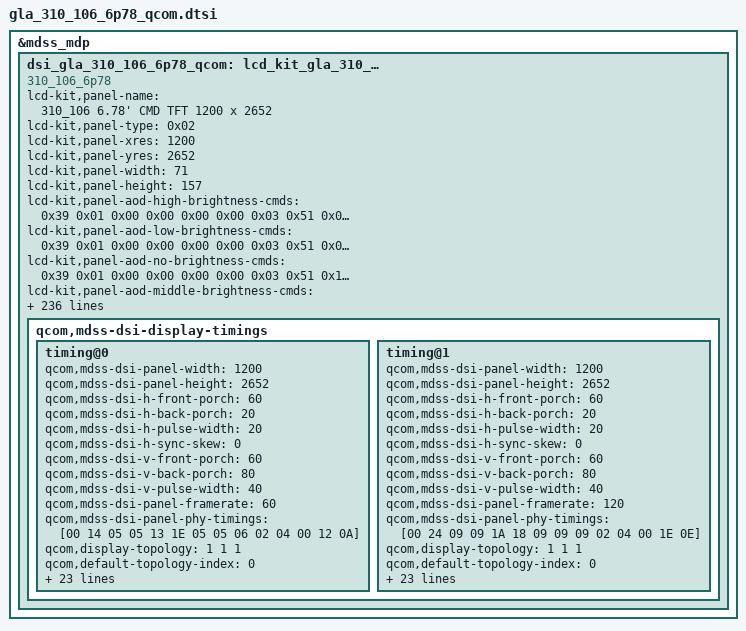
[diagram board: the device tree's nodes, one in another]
/* Copyright (c) 2013, The Linux Foundation. All rights reserved.
 *
 * This program is free software; you can redistribute it and/or modify
 * it under the terms of the GNU General Public License version 2 and
 * only version 2 as published by the Free Software Foundation.
 *
 * This program is distributed in the hope that it will be useful,
 * but WITHOUT ANY WARRANTY; without even the implied warranty of
 * MERCHANTABILITY or FITNESS FOR A PARTICULAR PURPOSE.  See the
 * GNU General Public License for more details.
 */

/*-------------------------------------------------------------------------
 * This file is autogenerated file using gcdb parser. Please do not edit it.
 * Update input XML file to add a new entry or update variable in this file
 * VERSION = 1.1
 *-----------------------------------------------------------------------*/
&mdss_mdp {
	dsi_gla_310_106_6p78_qcom: lcd_kit_gla_310_106_6p78_qcom {
		compatible = "310_106_6p78";
		lcd-kit,panel-name = "310_106 6.78' CMD TFT 1200 x 2652";
		lcd-kit,panel-type = <0x02>;
		lcd-kit,panel-xres = <1200>;
		lcd-kit,panel-yres = <2652>;
		lcd-kit,panel-width = <71>;
		lcd-kit,panel-height = <157>;
		lcd-kit,panel-aod-high-brightness-cmds = <0x39 0x01 0x00 0x00 0x00 0x00 0x03 0x51 0x0F 0xFE>;
		lcd-kit,panel-aod-low-brightness-cmds = <0x39 0x01 0x00 0x00 0x00 0x00 0x03 0x51 0x01 0x24>;
		lcd-kit,panel-aod-no-brightness-cmds = <0x39 0x01 0x00 0x00 0x00 0x00 0x03 0x51 0x10 0x00>;
		lcd-kit,panel-aod-middle-brightness-cmds = <0x39 0x01 0x00 0x00 0x00 0x00 0x03 0x51 0x06 0xDB>;
		lcd-kit,pcd-check-reg-cmds = <0x20>;
		lcd-kit,check-reg-on-cmds = <0x06 0x01 0x00 0x00 0x0a 0x00 0x01 0x0a>;
		lcd-kit,check-reg-on-value = <0x9c>;
		lcd-kit,check-aod-reg-on-cmds = <0x06 0x01 0x00 0x00 0x0a 0x00 0x01 0x0a>;
		lcd-kit,check-aod-reg-on-value = <0xdc>;
		lcd-kit,check-reg-off-cmds = <0x06 0x01 0x00 0x00 0x0a 0x00 0x01 0x0a>;
		lcd-kit,check-reg-off-value = <0x08>;
		lcd-kit,check-reg-on-cmds-state = "dsi_lp_mode";
		lcd-kit,check-aod-reg-on-cmds-state = "dsi_lp_mode";
		lcd-kit,check-reg-off-cmds-state = "dsi_lp_mode";
		lcd-kit,pcd-check-reg-value = <0x20>;
		lcd-kit,pcd-errflag-check-support = <0>;
		lcd-kit,checksum-enable-cmds = <0x39 0x01 0x00 0x00 0x14 0x00 0x05 0xFF 0xAA 0x55 0xA5 0x80
		0x15 0x01 0x00 0x00 0x0a 0x00 0x02 0xF2 0x03>;
		lcd-kit,checksum-enable-cmds-state = "dsi_lp_mode";
		lcd-kit,checksum-disable-cmds = <0x39 0x01 0x00 0x00 0x14 0x00 0x05 0xFF 0xAA 0x55 0xA5 0x80
		0x15 0x01 0x00 0x00 0x0a 0x00 0x02 0xF2 0x00>;
		lcd-kit,checksum-disable-cmds-state = "dsi_lp_mode";
		lcd-kit,checksum-cmds = <0x39 0x01 0x00 0x00 0x14 0x00 0x05 0xFF 0xAA 0x55 0xA5 0x80
		0x15 0x01 0x00 0x00 0x0a 0x00 0x02 0x6F 0x01
		0x14 0x01 0x00 0x00 0x0a 0x00 0x08 0xF2 0x00 0x00 0x00 0x00 0x00 0x00 0x00>;
		lcd-kit,checksum-cmds-state = "dsi_lp_mode";
		lcd-kit,checksum-value = <0x06 0xf2 0x7d 0x83 0x91 0xe7 0x4c 0x2a
		0xba 0xeb 0x79 0x7c 0xe4 0xb4 0xcb 0x62
		0x97 0x89 0xd0 0x7a 0xc4 0xee 0xf7 0x69>;
		lcd-kit,hor-line-cmds = <0x39 0x01 0x00 0x00 0x0a 0x00 0x06 0xF0 0x55 0xAA 0x52 0x08 0x01
		0x15 0x01 0x00 0x00 0x0a 0x00 0x02 0xB3 0x23
		0x15 0x01 0x00 0x00 0x0a 0x00 0x02 0xB4 0x23
		0x15 0x01 0x00 0x00 0x0a 0x00 0x02 0xB0 0x0B
		0x15 0x01 0x00 0x00 0x0a 0x00 0x02 0xB1 0x08
		0x39 0x01 0x00 0x00 0x0a 0x00 0x09 0xB7 0x46 0x46 0x46 0x46 0x46 0x46 0x46 0x46
		0x39 0x01 0x00 0x00 0x0a 0x00 0x08 0xB8 0x5F 0x5F 0x5F 0x5F 0x5F 0x5F 0x5F
		0x15 0x01 0x00 0x00 0x0a 0x00 0x02 0x2F 0x03
		0x39 0x01 0x00 0x00 0x0a 0x00 0x06 0xF0 0x55 0xAA 0x52 0x08 0x00
		0x39 0x01 0x00 0x00 0x0a 0x00 0x03 0xB2 0x11 0x00
		0x39 0x01 0x00 0x00 0x0a 0x00 0x03 0x51 0x00 0x00
		0x39 0x01 0x00 0x00 0x0a 0x00 0x06 0xF0 0x55 0xAA 0x52 0x08 0x06
		0x15 0x01 0x00 0x00 0x0a 0x00 0x02 0x6F 0x02
		0x39 0x01 0x00 0x00 0x0a 0x00 0x03 0xB1 0x31 0x31
		0x15 0x01 0x00 0x00 0x0a 0x00 0x02 0x6F 0x02
		0x39 0x01 0x00 0x00 0x0a 0x00 0x03 0xB7 0x31 0x31>;
		lcd-kit,hor-line-cmds-state = "dsi_lp_mode";
		lcd-kit,pcd-read-cmds = <0x15 0x01 0x00 0x00 0x00 0x00 0x02 0xB0 0x00
		0x15 0x01 0x00 0x00 0x00 0x00 0x02 0x00 0x00
		0x39 0x01 0x00 0x00 0x00 0x00 0x0D 0xDD 0x88 0x00 0x41 0x09 0x00 0x45 0x81 0x00 0x00 0x00 0x00 0x00
		0x39 0x01 0x00 0x00 0x00 0x00 0x0B 0xF7 0x00 0x00 0x00 0x00 0x00 0x00 0x00 0x00 0x20 0x00
		0x15 0x01 0x00 0x00 0x00 0x00 0x02 0xB0 0x00
		0x15 0x01 0x00 0x00 0x00 0x00 0x02 0x00 0x00
		0x15 0x01 0x00 0x00 0x00 0x00 0x02 0xF1 0x01
		0x06 0x01 0x00 0x00 0x00 0x00 0x01 0xB4
		0x15 0x01 0x00 0x00 0x00 0x00 0x02 0xB0 0x00
		0x15 0x01 0x00 0x00 0x00 0x00 0x02 0x00 0x00
		0x39 0x01 0x00 0x00 0x00 0x00 0x0D 0xDD 0x00 0x00 0x41 0x28 0x00 0x41 0x80 0x00 0x00 0x00 0x00 0x00
		0x39 0x01 0x00 0x00 0x00 0x00 0x0B 0xF7 0x00 0x00 0x00 0x00 0x00 0x00 0x00 0x00 0x00 0x00>;
		lcd-kit,pcd-read-cmds-state  = "dsi_lp_mode";
		lcd-kit,vtc-line-cmds = <0x39 0x01 0x00 0x00 0x0a 0x00 0x06 0xF0 0x55 0xAA 0x52 0x08 0x00
		0x15 0x01 0x00 0x00 0x0a 0x00 0x02 0x6F 0x06
		0x15 0x01 0x00 0x00 0x0a 0x00 0x02 0xB5 0x4E
		0x39 0x01 0x00 0x00 0x0a 0x00 0x06 0xF0 0x55 0xAA 0x52 0x08 0x01
		0x15 0x01 0x00 0x00 0x0a 0x00 0x02 0xCF 0x00
		0x39 0x01 0x00 0x00 0x0a 0x00 0x03 0xB5 0x00 0xF0
		0x39 0x01 0x00 0x00 0x0a 0x00 0x03 0xB6 0x01 0x60
		0x39 0x01 0x00 0x00 0x0a 0x00 0x06 0xF0 0x55 0xAA 0x52 0x08 0x00
		0x15 0x01 0x00 0x00 0x0a 0x00 0x02 0xC5 0x01
		0x39 0x01 0x00 0x00 0x0a 0x00 0x06 0xF0 0x55 0xAA 0x52 0x08 0x05
		0x15 0x01 0x00 0x00 0x0a 0x00 0x02 0xEC 0x01
		0x39 0x01 0x00 0x00 0x0a 0x00 0x03 0x51 0x0F 0xFF
		0x15 0x01 0x00 0x00 0x0a 0x00 0x02 0x53 0x20
		0x39 0x01 0x00 0x00 0x0a 0x00 0x06 0xF0 0x55 0xAA 0x52 0x08 0x01
		0x15 0x01 0x00 0x00 0x0a 0x00 0x02 0xB3 0x23
		0x15 0x01 0x00 0x00 0x0a 0x00 0x02 0xB4 0x23
		0x15 0x01 0x00 0x00 0x0a 0x00 0x02 0xB0 0x0B
		0x15 0x01 0x00 0x00 0x0a 0x00 0x02 0xB1 0x08
		0x39 0x01 0x00 0x00 0x0a 0x00 0x09 0xB7 0x46 0x46 0x46 0x46 0x46 0x46 0x46 0x46
		0x39 0x01 0x00 0x00 0x0a 0x00 0x08 0xB8 0x5F 0x5F 0x5F 0x5F 0x5F 0x5F 0x5F
		0x39 0x01 0x00 0x00 0x0a 0x00 0x06 0xF0 0x55 0xAA 0x52 0x08 0x07
		0x39 0x01 0x00 0x00 0x0a 0x00 0x07 0xB1 0x10 0x60 0x40 0x00 0x20 0x50
		0x05 0x01 0x00 0x00 0x46 0x01 0x01 0x11
		0x05 0x01 0x00 0x00 0x0a 0x01 0x01 0x28>;
		lcd-kit,vtc-line-cmds-state  = "dsi_lp_mode";
		lcd-kit,ddic-lv-det-enter1-cmds = <0x39 0x01 0x00 0x00 0x0a 0x00 0x06 0xF0 0x55 0xAA 0x52 0x08 0x01
		0x39 0x01 0x00 0x00 0x14 0x00 0x05 0xC7 0x68 0x34 0x30 0x0F>;
		lcd-kit,ddic-lv-det-enter1-cmds-state  = "dsi_lp_mode";
		lcd-kit,ddic-lv-det-enter2-cmds = <0x39 0x01 0x00 0x00 0x0a 0x00 0x06 0xF0 0x55 0xAA 0x52 0x08 0x01
		0x39 0x01 0x00 0x00 0x14 0x00 0x05 0xC7 0x68 0x34 0x30 0x0F>;
		lcd-kit,ddic-lv-det-enter2-cmds-state  = "dsi_lp_mode";
		lcd-kit,ddic-lv-det-enter3-cmds = <0x39 0x01 0x00 0x00 0x0a 0x00 0x06 0xF0 0x55 0xAA 0x52 0x08 0x01
		0x39 0x01 0x00 0x00 0x14 0x00 0x05 0xC7 0x68 0x34 0x30 0x0F>;
		lcd-kit,ddic-lv-det-enter3-cmds-state  = "dsi_lp_mode";
		lcd-kit,ddic-lv-det-enter4-cmds = <0x39 0x01 0x00 0x00 0x0a 0x00 0x06 0xF0 0x55 0xAA 0x52 0x08 0x01
		0x39 0x01 0x00 0x00 0x14 0x00 0x05 0xC7 0x68 0x34 0x30 0x0F>;
		lcd-kit,ddic-lv-det-enter4-cmds-state  = "dsi_lp_mode";
		lcd-kit,ddic-lv-det-rd1-cmds = <0x06 0x01 0x00 0x00 0x0a 0x00 0x01 0x0a>;
		lcd-kit,ddic-lv-det-rd1-cmds-state  = "dsi_lp_mode";
		lcd-kit,ddic-lv-det-rd2-cmds = <0x06 0x01 0x00 0x00 0x0a 0x00 0x01 0x0a>;
		lcd-kit,ddic-lv-det-rd2-cmds-state  = "dsi_lp_mode";
		lcd-kit,ddic-lv-det-rd3-cmds = <0x06 0x01 0x00 0x00 0x0a 0x00 0x01 0x0a>;
		lcd-kit,ddic-lv-det-rd3-cmds-state  = "dsi_lp_mode";
		lcd-kit,ddic-lv-det-rd4-cmds = <0x06 0x01 0x00 0x00 0x0a 0x00 0x01 0x0a>;
		lcd-kit,ddic-lv-det-rd4-cmds-state  = "dsi_lp_mode";
		lcd-kit,ddic-lv-det-value1 = <0x9c>;
		lcd-kit,ddic-lv-det-value2 = <0x9c>;
		lcd-kit,ddic-lv-det-value3 = <0x9c>;
		lcd-kit,ddic-lv-det-value4 = <0x9c>;
		lcd-kit,bl-after-frame = <0>;
		lcd-kit,cmd-async-support = <0>;
		lcd-kit,ap-aod-support = <1>;
		lcd-kit,mask-delay-time-before-fp = <16667>;
		lcd-kit,mask-delay-time-after-fp = <16667>;
		lcd-kit,left-time-to-te-us = <28667>;
		lcd-kit,right-time-to-te-us = <29667>;
		lcd-kit,te-interval-time-us = <16667>;
		lcd-kit,oneside-mode-support = <0>;
		lcd-kit,color-aod-detect-support = <0>;
		lcd-kit,elvdd-detect-support = <0>;
		lcd-kit,elvdd-detect-type = <2>;
		lcd-kit,elvdd-detect-value = <1>;
		lcd-kit,elvdd-delay = <50>;
		lcd-kit,elvdd-detect-gpio = <104>;
		lcd-kit,check-reg-on-support = <0>;
		lcd-kit,check-reg-on-support-dsm-report = <0>;
		lcd-kit,check-aod-reg-on-support = <0>;
		lcd-kit,check-aod-reg-on-support-dsm-report = <0>;
		lcd-kit,check-reg-off-support = <0>;
		lcd-kit,check-reg-off-support-dsm-report = <0>;
		lcd-kit,checksum-support = <0>;
		lcd-kit,pcd-cmds-support = <1>;
		lcd-kit,pcd-check-reg-value-compare-mode = <0>;
		lcd-kit,vtc-line-support = <0>;
		lcd-kit,ddic-lv-det-support = <0>;
		lcd-kit,hor-line-support = <0>;
		lcd-kit,hor-line-duration = <600>;
		lcd-kit,vtc-line-no-reset = <1>;
		qcom,mdss-dsi-panel-type = "dsi_cmd_mode";
		qcom,mdss-pan-physical-width-dimension = <71>;
		qcom,mdss-pan-physical-height-dimension = <157>;
		qcom,dsi-ctrl-num = <0>;
		qcom,dsi-phy-num = <0>;
		qcom,panel-supply-entries = <&dsi_panel_pwr_supply>;
		qcom,mdss-dsi-virtual-channel-id = <0>;
		qcom,mdss-dsi-h-sync-pulse = <0>;
		qcom,mdss-dsi-bllp-eof-power-mode;
		qcom,mdss-dsi-bllp-power-mode;
		qcom,mdss-dsi-dma-schedule-line = <1>;
		qcom,mdss-dsi-bpp = <24>;
		qcom,mdss-dsi-color-order = "rgb_swap_rgb";
		qcom,mdss-dsi-underflow-color = <0xff>;
		qcom,mdss-dsi-border-color = <0>;
		qcom,mdss-dsi-traffic-mode = "burst_mode";
		qcom,mdss-dsi-lane-map = "lane_map_0123";
		qcom,mdss-dsi-lane-0-state;
		qcom,mdss-dsi-lane-1-state;
		qcom,mdss-dsi-lane-2-state;
		qcom,mdss-dsi-lane-3-state;
		qcom,mdss-dsi-mdp-trigger = "none";
		qcom,mdss-dsi-dma-trigger = "trigger_sw";
		qcom,mdss-dsi-te-pin-select = <1>;
		qcom,mdss-dsi-wr-mem-start = <0x2c>;
		qcom,mdss-dsi-wr-mem-continue = <0x3c>;
		qcom,mdss-dsi-te-dcs-command = <1>;
		qcom,mdss-dsi-te-check-enable;
		qcom,mdss-dsi-te-using-te-pin;
		qcom,dsi-panel-gpio-address = <0x0F100000 0x1000>;
		qcom,dsi-panel-gpio-pins = <12 44 80>;
		qcom,dsi-panel-gpio-names = "reg-gpio", "reset-gpio", "platform-te-gpio";
		qcom,mdss-dsi-t-clk-post = <0>;
		qcom,mdss-dsi-t-clk-pre = <0>;
		qcom,dsi-select-clocks = "mux_byte_clk0", "mux_pixel_clk0";
		qcom,mdss-dsi-stream = <0>;
		lcd-kit,check-thread-support = <0>;
		lcd-kit,check-time-period = <5000>;
		lcd-kit,check-fold-support = <0>;
		lcd-kit,fold-low-power-support = <0>;
		lcd-kit,fold-height = <0>;
		lcd-kit,unfold-height = <0>;
		lcd-kit,power-support = <0>;
		lcd-kit,three-stage-poweron = <1>;
		lcd-kit,fold-lp-time = <0>;
		lcd-kit,fold-nolp-time = <0>;
		qcom,sublinks-count = <2>;
		qcom,lanes-per-sublink = <2>;
		qcom,mdss-dsi-panel-hdr-color-primaries = <14500 15500 32000 17000 15500 30000 8000 3000>;
		qcom,mdss-dsi-panel-peak-brightness = <4200000>;
		qcom,mdss-dsi-panel-blackness-level = <3230>;
		qcom,dynamic-mode-switch-enabled;
		qcom,dynamic-mode-switch-type = "dynamic-resolution-switch-immediate";
		qcom,mdss-dsi-bl-pmic-control-type = "bl_ctrl_dcs";
		qcom,mdss-dsi-bl-min-level = <1>;
		qcom,mdss-dsi-bl-max-level = <10000>;
		qcom,esd-check-enabled;
		qcom,mdss-dsi-panel-status-command = [06 01 00 00 00 00 01 0A
			06 01 00 00 00 00 01 03
			15 01 00 00 00 00 02 B0 00
			15 01 00 00 00 00 02 00 00
			06 01 00 00 00 00 02 F8 00
			06 01 00 00 00 00 01 C3
			15 01 00 00 00 00 02 B0 03
			15 01 00 00 00 00 02 00 00];
		qcom,mdss-dsi-panel-status-command-state = "dsi_lp_mode";
		qcom,mdss-dsi-panel-status-check-mode = "reg_read";
		qcom,mdss-dsi-panel-status-read-length = <1 1 0 0 2 1 0 0>;
		qcom,mdss-dsi-panel-status-value = <0x1C>,<0x00>,<0x11 0x00>,<0x00>;
		lcd-kit,power-on-stage = <2 1 3
				1 1 1
				9 1 15>;
		lcd-kit,lp-on-stage = <5 1 5
				5 0 2
				5 1 30
				7 1 0
				6 1 0
				8 1 0>;
		lcd-kit,lp-off-stage = <0 0 0>;
		lcd-kit,power-off-stage = <7 0 0
				6 0 0
				8 0 0
				5 0 2
				9 0 1
				1 0 2
				2 0 1>;
		lcd-kit,only-power-off-stage = <0 0 0>;
		lcd-kit,pt-support = <1>;
		lcd-kit,panel-on-always-reset = <0>;
		lcd-kit,lcd-vci = <1 13 3000000 3000000 3000000 10000 80>;
		lcd-kit,lcd-iovcc = <1 12 1800000 1800000 1800000 60700 80>;
		lcd-kit,lcd-vdd = <1 16 1240000 1240000 1240000 30000 80>;
		lcd-kit,lcd-reset = <2 44 0>;
		lcd-kit,lcd-vci-name = "vdd";
		lcd-kit,lcd-iovcc-name = "vddio";
		lcd-kit,lcd-vdd-name = "ddic";
		lcd-kit,project-id-support = <0>;
		lcd-kit,default-project-id = "B2359S2920";
		lcd-kit,sn-code-support = <1>;
		lcd-kit,oem-info-support = <1>;
		lcd-kit,oem-barcode-2d-support = <1>;
		lcd-kit,oem-barcode-2d-num-offset = <0>;
		lcd-kit,barcode-2d-cmds = <0x15 0x01 0x00 0x00 0x00 0x00 0x02 0xB0 0x40
		0x15 0x01 0x00 0x00 0x00 0x00 0x02 0x00 0x00
		0x14 0x01 0x00 0x00 0x00 0x00 0x15 0xBE 0x00 0x00 0x00 0x00 0x00 0x00 0x00 0x00 0x00 0x00 0x00 0x00 0x00 0x00 0x00 0x00 0x00 0x00 0x00 0x00
		0x15 0x01 0x00 0x00 0x00 0x00 0x02 0xB0 0x03
		0x15 0x01 0x00 0x00 0x00 0x00 0x02 0x00 0x00>;
		lcd-kit,barcode-2d-cmds-state = "dsi_lp_mode";
		lcd-kit,panel-getblmaxnit-type = <0>;
		lcd-kit,panel-blmaxnit-min-value = <400>;
		lcd-kit,inversion-support = <0>;
		lcd-kit,panel-gpio-offset = <336>;
		lcd-kit,finger-unlock-state-support = <0>;
		lcd-kit,finger-handle-esd-support = <1>;
		lcd-kit,esd-reg-te-check = <0>;
		lcd-kit,dump-support = <0>;
		lcd-kit,underflow-support = <1>;
		lcd-kit,panel-bl-max-nit = <450>;
		lcd-kit,panel-bl-min = <9>;
		lcd-kit,panel-bl-max = <10000>;
		lcd-kit,panel-bl-def = <2047>;
		lcd-kit,check-reg-support = <0>;
		lcd-kit,thp-proximity-support = <0>;
		lcd-kit,proximity-reset-delay-min = <65>;
		lcd-kit,backlight-cmds = <0x39 0x01 0x00 0x00 0x00 0x00 0x03 0x51 0x00 0x00>;
		lcd-kit,backlight-cmds-state = "dsi_lp_mode";
		lcd-kit,backlight-order = <0>;
		lcd-kit,backlight-need-sync = <0>;
		lcd-kit,backlight-write-offset = <0x10>;
		lcd-kit,fps-support = <1>;
		lcd-kit,default-fps = <60>;
		lcd-kit,panel-support-fps-list = <60 120>;
		lcd-kit,fps-60-cmd = "vndservice call display.qservice 25 i32 0 i32 0";
		lcd-kit,fps-90-cmd = "vndservice call display.qservice 25 i32 2 i32 0";
		lcd-kit,fps-120-cmd = "vndservice call display.qservice 25 i32 1 i32 0";
		qcom,mdss-dsi-display-timings {
			timing@0 {
				qcom,mdss-dsi-panel-width = <1200>;
				qcom,mdss-dsi-panel-height = <2652>;
				qcom,mdss-dsi-h-front-porch = <60>;
				qcom,mdss-dsi-h-back-porch = <20>;
				qcom,mdss-dsi-h-pulse-width = <20>;
				qcom,mdss-dsi-h-sync-skew = <0>;
				qcom,mdss-dsi-v-front-porch = <60>;
				qcom,mdss-dsi-v-back-porch = <80>;
				qcom,mdss-dsi-v-pulse-width = <40>;
				qcom,mdss-dsi-panel-framerate = <60>;
				qcom,mdss-dsi-panel-phy-timings= [00 14 05 05 13 1E 05
			05 06 02 04 00 12 0A];
				qcom,display-topology  = <1 1 1>;
				qcom,default-topology-index  = <0>;
				qcom,mdss-dsi-on-command = [15 01 00 00 00 00 02 B0 00
		15 01 00 00 00 00 02 00 00
		15 01 00 00 00 00 02 F1 03
		15 01 00 00 00 00 02 F8 AB
		15 01 00 00 00 00 02 F1 24
		39 01 00 00 00 00 08 F8 07 10 20 00 06 0F 0F
		15 01 00 00 00 00 02 F1 3A
		39 01 00 00 00 00 1F F8 02 02 22 00 2A 40 2A BE 3A FC 3A FA 3A F8 3B 38 3B 78 3B B6 4B B6 4B F4 4B F4 6C 34 84 74
		15 01 00 00 00 00 02 B0 00
		15 01 00 00 00 00 02 00 00
		39 01 00 00 00 00 03 F6 88 88
		15 01 00 00 00 00 02 B0 20
		15 01 00 00 00 00 02 00 00
		15 01 00 00 00 00 02 C2 39
		15 01 00 00 00 00 02 B0 00
		15 01 00 00 00 00 02 00 00
		39 01 00 00 00 00 04 E3 00 00 01
		39 01 00 00 00 00 04 B2 30 6C A6
		15 01 00 00 00 00 02 B0 04
		15 01 00 00 00 00 02 00 00
		15 01 00 00 00 00 02 DE 40
		15 01 00 00 00 00 02 80 01
		39 01 00 00 00 00 05 2A 00 00 04 AF
		39 01 00 00 00 00 05 2B 00 00 0A 5B
		15 01 00 00 00 00 02 35 00
		15 01 00 00 00 00 02 53 20
		15 01 00 00 00 00 02 B0 03
		15 01 00 00 00 00 02 00 00
		05 01 00 00 A0 00 01 11
		05 01 00 00 14 00 01 29];
				qcom,mdss-dsi-on-command-state = "dsi_lp_mode";
				qcom,mdss-dsi-off-command = [05 01 00 00 00 00 01 28
		05 01 00 00 5D 00 01 10];
				qcom,mdss-dsi-off-command-state = "dsi_lp_mode";
				qcom,compression-mode = "dsc";
				qcom,mdss-dsc-slice-height = <12>;
				qcom,mdss-dsc-slice-width = <600>;
				qcom,mdss-dsc-slice-per-pkt = <2>;
				qcom,mdss-dsc-bit-per-component = <10>;
				qcom,mdss-dsc-bit-per-pixel = <8>;
				qcom,mdss-dsc-block-prediction-enable;
				qcom,mdss-dsi-timing-switch-command = [15 01 00 00 11 00 02 80 01];
				qcom,mdss-dsi-timing-switch-command-state = "dsi_lp_mode";
				qcom,mdss-dsi-lp1-command = [39 01 00 00 00 00 03 51 10 00
		15 01 00 00 00 00 02 B0 00
		15 01 00 00 00 00 02 00 00
		15 01 00 00 00 00 02 F1 09
		39 01 00 00 00 00 03 C5 00 AA
		15 01 00 00 00 00 02 B0 03
		15 01 00 00 00 00 02 00 00
		05 01 00 00 00 00 01 39];
				qcom,mdss-dsi-lp1-command-state = "dsi_lp_mode";
				qcom,mdss-dsi-nolp-command = [39 01 00 00 00 00 03 51 10 00
		15 01 00 00 00 00 02 B0 00
		15 01 00 00 00 00 02 00 00
		15 01 00 00 00 00 02 F1 09
		39 01 00 00 00 00 03 C5 05 0A
		15 01 00 00 00 00 02 B0 03
		15 01 00 00 00 00 02 00 00
		05 01 00 00 00 00 01 38];
				qcom,mdss-dsi-nolp-command-state = "dsi_lp_mode";
			};
			timing@1 {
				qcom,mdss-dsi-panel-width = <1200>;
				qcom,mdss-dsi-panel-height = <2652>;
				qcom,mdss-dsi-h-front-porch = <60>;
				qcom,mdss-dsi-h-back-porch = <20>;
				qcom,mdss-dsi-h-pulse-width = <20>;
				qcom,mdss-dsi-h-sync-skew = <0>;
				qcom,mdss-dsi-v-front-porch = <60>;
				qcom,mdss-dsi-v-back-porch = <80>;
				qcom,mdss-dsi-v-pulse-width = <40>;
				qcom,mdss-dsi-panel-framerate = <120>;
				qcom,mdss-dsi-panel-phy-timings= [00 24 09 09 1A 18 09
			09 09 02 04 00 1E 0E];
				qcom,display-topology  = <1 1 1>;
				qcom,default-topology-index  = <0>;
				qcom,mdss-dsi-on-command = [15 01 00 00 00 00 02 B0 00
		15 01 00 00 00 00 02 00 00
		15 01 00 00 00 00 02 F1 03
		15 01 00 00 00 00 02 F8 AB
		15 01 00 00 00 00 02 F1 24
		39 01 00 00 00 00 08 F8 07 10 20 00 06 0F 0F
		15 01 00 00 00 00 02 F1 3A
		39 01 00 00 00 00 1F F8 02 02 22 00 2A 40 2A BE 3A FC 3A FA 3A F8 3B 38 3B 78 3B B6 4B B6 4B F4 4B F4 6C 34 84 74
		15 01 00 00 00 00 02 B0 00
		15 01 00 00 00 00 02 00 00
		39 01 00 00 00 00 03 F6 88 88
		15 01 00 00 00 00 02 B0 20
		15 01 00 00 00 00 02 00 00
		15 01 00 00 00 00 02 C2 39
		15 01 00 00 00 00 02 B0 00
		15 01 00 00 00 00 02 00 00
		39 01 00 00 00 00 04 E3 00 00 01
		39 01 00 00 00 00 04 B2 30 6C A6
		15 01 00 00 00 00 02 B0 04
		15 01 00 00 00 00 02 00 00
		15 01 00 00 00 00 02 DE 40
		15 01 00 00 00 00 02 80 10
		39 01 00 00 00 00 05 2A 00 00 04 AF
		39 01 00 00 00 00 05 2B 00 00 0A 5B
		15 01 00 00 00 00 02 35 00
		15 01 00 00 00 00 02 53 20
		15 01 00 00 00 00 02 B0 03
		15 01 00 00 00 00 02 00 00
		05 01 00 00 A0 00 01 11
		05 01 00 00 14 00 01 29];
				qcom,mdss-dsi-on-command-state = "dsi_lp_mode";
				qcom,mdss-dsi-off-command = [05 01 00 00 00 00 01 28
		05 01 00 00 5D 00 01 10];
				qcom,mdss-dsi-off-command-state = "dsi_lp_mode";
				qcom,compression-mode = "dsc";
				qcom,mdss-dsc-slice-height = <12>;
				qcom,mdss-dsc-slice-width = <600>;
				qcom,mdss-dsc-slice-per-pkt = <2>;
				qcom,mdss-dsc-bit-per-component = <10>;
				qcom,mdss-dsc-bit-per-pixel = <8>;
				qcom,mdss-dsc-block-prediction-enable;
				qcom,mdss-dsi-timing-switch-command = [15 01 00 00 11 00 02 80 10];
				qcom,mdss-dsi-timing-switch-command-state = "dsi_lp_mode";
				qcom,mdss-dsi-lp1-command = [15 01 00 00 11 00 02 80 01
		39 01 00 00 00 00 03 51 10 00
		15 01 00 00 00 00 02 B0 00
		15 01 00 00 00 00 02 00 00
		15 01 00 00 00 00 02 F1 09
		39 01 00 00 00 00 03 C5 00 AA
		15 01 00 00 00 00 02 B0 03
		15 01 00 00 00 00 02 00 00
		05 01 00 00 00 00 01 39];
				qcom,mdss-dsi-lp1-command-state = "dsi_lp_mode";
				qcom,mdss-dsi-nolp-command = [15 01 00 00 11 00 02 80 10
		39 01 00 00 00 00 03 51 10 00
		15 01 00 00 00 00 02 B0 00
		15 01 00 00 00 00 02 00 00
		15 01 00 00 00 00 02 F1 09
		39 01 00 00 00 00 03 C5 05 0A
		15 01 00 00 00 00 02 B0 03
		15 01 00 00 00 00 02 00 00
		05 01 00 00 00 00 01 38];
				qcom,mdss-dsi-nolp-command-state = "dsi_lp_mode";
			};
		};
    };
};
